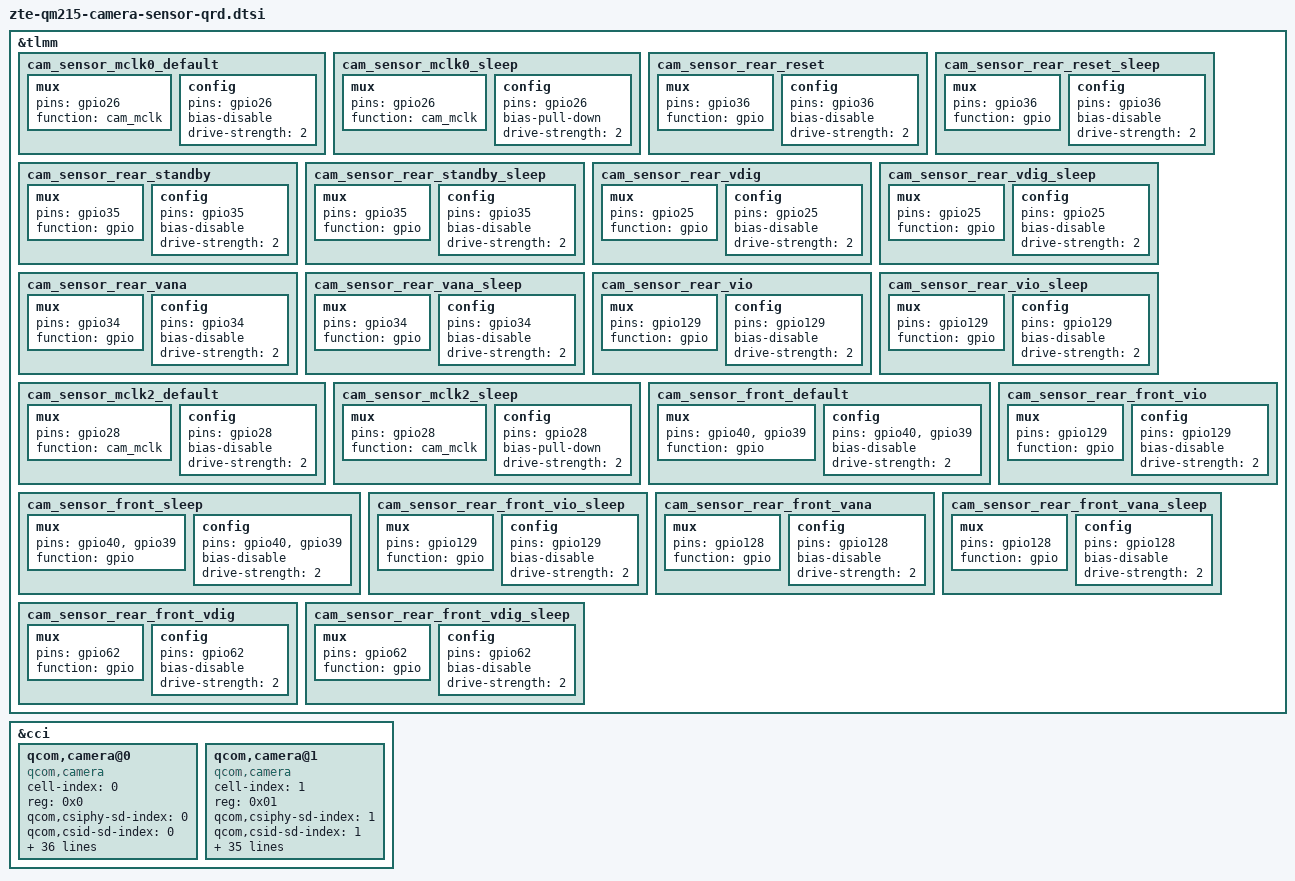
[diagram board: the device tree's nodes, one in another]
/*
 * Copyright (c) 2018-2019 The Linux Foundation. All rights reserved.
 *
 * This program is free software; you can redistribute it and/or modify
 * it under the terms of the GNU General Public License version 2 and
 * only version 2 as published by the Free Software Foundation.
 *
 * This program is distributed in the hope that it will be useful,
 * but WITHOUT ANY WARRANTY; without even the implied warranty of
 * MERCHANTABILITY or FITNESS FOR A PARTICULAR PURPOSE.  See the
 * GNU General Public License for more details.
 */
&tlmm{
		cam_sensor_mclk0_default: cam_sensor_mclk0_default {
			/* MCLK0 */
			mux {
				/* CLK, DATA */
				pins = "gpio26";
				function = "cam_mclk";
			};

			config {
				pins = "gpio26";
				bias-disable; /* No PULL */
				drive-strength = <2>; /* 2 MA */
			};
		};

		cam_sensor_mclk0_sleep: cam_sensor_mclk0_sleep {
			/* MCLK0 */
			mux {
				/* CLK, DATA */
				pins = "gpio26";
				function = "cam_mclk";
			};

			config {
				pins = "gpio26";
				bias-pull-down; /* PULL DOWN */
				drive-strength = <2>; /* 2 MA */
			};
		};

		cam_sensor_rear_reset: cam_sensor_rear_reset {
			/* RESET */
			mux {
				pins = "gpio36";
				function = "gpio";
			};

			config {
				pins = "gpio36";
				bias-disable; /* No PULL */
				drive-strength = <2>; /* 2 MA */
			};
		};

		cam_sensor_rear_reset_sleep: cam_sensor_rear_reset_sleep {
			/* RESET */
			mux {
				pins = "gpio36";
				function = "gpio";
			};

			config {
				pins = "gpio36";
				bias-disable; /* No PULL */
				drive-strength = <2>; /* 2 MA */
			};
		};

		cam_sensor_rear_standby: cam_sensor_rear_standby {
			/* STANDBY */
			mux {
				pins = "gpio35";
				function = "gpio";
			};

			config {
				pins = "gpio35";
				bias-disable; /* No PULL */
				drive-strength = <2>; /* 2 MA */
			};
		};

		cam_sensor_rear_standby_sleep: cam_sensor_rear_standby_sleep {
			/* STANDBY */
			mux {
				pins = "gpio35";
				function = "gpio";
			};

			config {
				pins = "gpio35";
				bias-disable; /* No PULL */
				drive-strength = <2>; /* 2 MA */
			};
		};

		cam_sensor_rear_vdig: cam_sensor_rear_vdig {
			/* VDIG */
			mux {
				pins = "gpio25";
				function = "gpio";
			};

			config {
				pins = "gpio25";
				bias-disable; /* No PULL */
				drive-strength = <2>; /* 2 MA */
			};
		};

		cam_sensor_rear_vdig_sleep: cam_sensor_rear_vdig_sleep {
			/* VDIG */
			mux {
				pins = "gpio25";
				function = "gpio";
			};

			config {
				pins = "gpio25";
				bias-disable; /* No PULL */
				drive-strength = <2>; /* 2 MA */
			};
		};

		cam_sensor_rear_vana: cam_sensor_rear_vana {
			/* VANA */
			mux {
				pins = "gpio34";
				function = "gpio";
			};

			config {
				pins = "gpio34";
				bias-disable; /* No PULL */
				drive-strength = <2>; /* 2 MA */
			};
		};

		cam_sensor_rear_vana_sleep: cam_sensor_rear_vana_sleep {
			/* VANA */
			mux {
				pins = "gpio34";
				function = "gpio";
			};

			config {
				pins = "gpio34";
				bias-disable; /* No PULL */
				drive-strength = <2>; /* 2 MA */
			};
		};
		cam_sensor_rear_vio: cam_sensor_rear_vio {
			/* VANA */
			mux {
				pins = "gpio129";
				function = "gpio";
			};

			config {
				pins = "gpio129";
				bias-disable; /* No PULL */
				drive-strength = <2>; /* 2 MA */
			};
		};

		cam_sensor_rear_vio_sleep: cam_sensor_rear_vio_sleep {
			/* VANA */
			mux {
				pins = "gpio129";
				function = "gpio";
			};

			config {
				pins = "gpio129";
				bias-disable; /* No PULL */
				drive-strength = <2>; /* 2 MA */
			};
		};

		cam_sensor_mclk2_default: cam_sensor_mclk2_default {
			/* MCLK2 */
			mux {
				/* CLK, DATA */
				pins = "gpio28";
				function = "cam_mclk";
			};

			config {
				pins = "gpio28";
				bias-disable; /* No PULL */
				drive-strength = <2>; /* 2 MA */
			};
		};

		cam_sensor_mclk2_sleep: cam_sensor_mclk2_sleep {
			/* MCLK2 */
			mux {
				/* CLK, DATA */
				pins = "gpio28";
				function = "cam_mclk";
			};

			config {
				pins = "gpio28";
				bias-pull-down; /* PULL DOWN */
				drive-strength = <2>; /* 2 MA */
			};
		};

		cam_sensor_front_default: cam_sensor_front_default {
			/* RESET, STANDBY */
			mux {
				pins = "gpio40", "gpio39";
				function = "gpio";
			};

			config {
				pins = "gpio40", "gpio39";
				bias-disable; /* No PULL */
				drive-strength = <2>; /* 2 MA */
			};
		};

		cam_sensor_front_sleep: cam_sensor_front_sleep {
			/* RESET, STANDBY */
			mux {
				pins = "gpio40", "gpio39";
				function = "gpio";
			};

			config {
				pins = "gpio40", "gpio39";
				bias-disable; /* No PULL */
				drive-strength = <2>; /* 2 MA */
			};
		};
		cam_sensor_rear_front_vio: cam_sensor_rear_front_vio {
		mux {
			pins = "gpio129";
			function = "gpio";
		};

		config {
			pins = "gpio129";
			bias-disable; /* No PULL */
			drive-strength = <2>; /* 2 MA */
		};
	};

	cam_sensor_rear_front_vio_sleep: cam_sensor_rear_front_vio_sleep {
		/* VIO */
		mux {
			pins = "gpio129";
			function = "gpio";
		};

		config {
			pins = "gpio129";
			bias-disable; /* No PULL */
			drive-strength = <2>; /* 2 MA */
		};
	};
	cam_sensor_rear_front_vana: cam_sensor_rear_front_vana {
		mux {
			pins = "gpio128";
			function = "gpio";
		};

		config {
			pins = "gpio128";
			bias-disable; /* No PULL */
			drive-strength = <2>; /* 2 MA */
		};
	};

	cam_sensor_rear_front_vana_sleep: cam_sensor_rear_front_vana_sleep {
		/* VIO */
		mux {
			pins = "gpio128";
			function = "gpio";
		};

		config {
			pins = "gpio128";
			bias-disable; /* No PULL */
			drive-strength = <2>; /* 2 MA */
		};
	};
	cam_sensor_rear_front_vdig: cam_sensor_rear_front_vdig {
		mux {
			pins = "gpio62";
			function = "gpio";
		};

		config {
			pins = "gpio62";
			bias-disable; /* No PULL */
			drive-strength = <2>; /* 2 MA */
		};
	};

	cam_sensor_rear_front_vdig_sleep: cam_sensor_rear_front_vdig_sleep {
		/* VIO */
		mux {
			pins = "gpio62";
			function = "gpio";
		};

		config {
			pins = "gpio62";
			bias-disable; /* No PULL */
			drive-strength = <2>; /* 2 MA */
		};
	};
};
&cci {
	#address-cells = <1>;
	#size-cells = <0>;

	qcom,camera@0 {
		cell-index = <0>;
		compatible = "qcom,camera";
		reg = <0x0>;
		qcom,csiphy-sd-index = <0>;
		qcom,csid-sd-index = <0>;
		qcom,mount-angle = <90>;
		//qcom,led-flash-src = <&flash0>;
		//qcom,actuator-src = <&actuator0>;
		//qcom,eeprom-src = <&eeprom0>;
		cam_vdig-supply = <&pm8916_s4>;
		//cam_vio-supply = <&pm8916_l6>;
		//cam_vaf-supply = <&pm8916_l10>;
		qcom,cam-vreg-name = "cam_vdig";
		qcom,cam-vreg-min-voltage = <2100000>;
		qcom,cam-vreg-max-voltage = <2100000>;
		qcom,cam-vreg-op-mode = <80000>;
		qcom,gpio-no-mux = <0>;
		pinctrl-names = "cam_default", "cam_suspend";
		pinctrl-0 = <&cam_sensor_mclk0_default
				&cam_sensor_rear_vdig
				&cam_sensor_rear_vana
				&cam_sensor_rear_vio
				&cam_sensor_rear_standby
				&cam_sensor_rear_reset>;
		pinctrl-1 = <&cam_sensor_mclk0_sleep
				&cam_sensor_rear_vdig_sleep
				&cam_sensor_rear_vana_sleep
				&cam_sensor_rear_vio_sleep
				&cam_sensor_rear_standby_sleep
				&cam_sensor_rear_reset_sleep>;
		gpios = <&tlmm 26 0>,
		    <&tlmm 25 0>,
			<&tlmm 34 0>,
			<&tlmm 129 0>,
			<&tlmm 35 0>,
			<&tlmm 36 0>;
		qcom,gpio-vdig = <1>;
		qcom,gpio-vana = <2>;
		qcom,gpio-vio = <3>;
		qcom,gpio-standby = <4>;
		qcom,gpio-reset = <5>;
		qcom,gpio-req-tbl-num = <0 1 2 3 4 5>;
		qcom,gpio-req-tbl-flags = <1 0 0 0 0 0>;
		qcom,gpio-req-tbl-label = "CAMIF_MCLK0",
		    "CAM_VDIG",
			"CAM_VANA",
			"CAM_VIO",
			"CAM_STANDBY0",
			"CAM_RESET0";
		qcom,sensor-position = <0>;
		qcom,sensor-mode = <0>;
		qcom,cci-master = <0>;
		clocks = <&clock_gcc clk_mclk0_clk_src>,
			<&clock_gcc clk_gcc_camss_mclk0_clk>;
		clock-names = "cam_src_clk", "cam_clk";
		qcom,clock-rates = <24000000 0>;
	};

	qcom,camera@1 {
		cell-index = <1>;
		compatible = "qcom,camera";
		reg = <0x01>;
		qcom,csiphy-sd-index = <1>;
		qcom,csid-sd-index = <1>;
		//qcom,eeprom-src = <&eeprom2>;
		qcom,mount-angle = <270>;
		//cam_vana-supply = <&pm8916_l16>;
		cam_vio-supply = <&pm8916_l6>;
		//cam_vaf-supply = <&pm8916_l10>;
		qcom,cam-vreg-name = "cam_vio";
		qcom,cam-vreg-min-voltage = <2800000>;
		qcom,cam-vreg-max-voltage = <2800000>;
		qcom,cam-vreg-op-mode = <80000>;
		qcom,gpio-no-mux = <0>;
		pinctrl-names = "cam_default", "cam_suspend";
		pinctrl-0 = <&cam_sensor_mclk2_default
				&cam_sensor_front_default
				&cam_sensor_rear_front_vana
				&cam_sensor_rear_front_vdig
				&cam_sensor_rear_front_vio>;
		pinctrl-1 = <&cam_sensor_mclk2_sleep
				&cam_sensor_front_sleep
				&cam_sensor_rear_front_vana_sleep
				&cam_sensor_rear_front_vdig_sleep
				&cam_sensor_rear_front_vio_sleep>;
		gpios = <&tlmm 28 0>,
			<&tlmm 128 0>,
			<&tlmm 62 0>,
			<&tlmm 40 0>,
			<&tlmm 39 0>,
			<&tlmm 129 0>;
		qcom,gpio-reset = <3>;
		qcom,gpio-vana = <1>;
		qcom,gpio-vdig = <2>;
		qcom,gpio-standby = <4>;
		qcom,gpio-vio = <5>;
		qcom,gpio-req-tbl-num = <0 1 2 3 4 5>;
		qcom,gpio-req-tbl-flags = <1 0 0 0 0 0>;
		qcom,gpio-req-tbl-label = "CAMIF_MCLK2",
			"CAM_VANA1",
			"CAM_VDIG1",
			"CAM_RESET1",
			"CAM_STANDBY1",
			"CAM_VIO1";
		qcom,sensor-position = <1>;
		qcom,sensor-mode = <0>;
		qcom,cci-master = <1>;
		clocks = <&clock_gcc clk_mclk2_clk_src>,
			<&clock_gcc clk_gcc_camss_mclk2_clk>;
		clock-names = "cam_src_clk", "cam_clk";
		qcom,clock-rates = <24000000 0>;
	};
};
